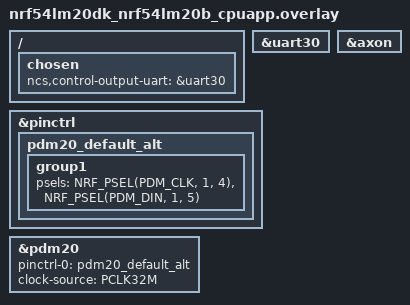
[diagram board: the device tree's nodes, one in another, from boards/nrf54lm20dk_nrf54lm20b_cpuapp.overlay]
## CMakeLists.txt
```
# SPDX-License-Identifier: Apache-2.0

cmake_minimum_required(VERSION 3.20.0)

# Include application-specific Kconfig before finding Zephyr
set(KCONFIG_ROOT ${CMAKE_CURRENT_SOURCE_DIR}/Kconfig)

find_package(Zephyr REQUIRED HINTS $ENV{ZEPHYR_BASE})
project(nrf54lm20b_wakeword_gated_kws)

# Note: The nrf_edgeai library is linked directly in zephyr/CMakeLists.txt using zephyr_link_libraries(),
# and the axon-ml SDK sources are added directly to Zephyr via zephyr_sources() in the same CMakeLists.txt.

target_sources(app PRIVATE src/main.cpp
    src/models/wakeword/nrf_edgeai_generated/nrf_edgeai_user_model.c
    src/models/kws/nrf_edgeai_generated/nrf_edgeai_user_model.c
    src/dmic.c
)
```

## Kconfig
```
# Application Kconfig
# This sources the Axon ML Kconfig options
source "Kconfig.zephyr"

rsource "../../lib/axon/zephyr/Kconfig.nrf_axon"
```

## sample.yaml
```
sample:
  description: Continuous DMIC audio pipeline that waits for the "Okay Nordic" wakeword, then runs nRF Edge AI keyword spotting in a 7-second active window and returns to wakeword mode on timeout.
  name: Wakeword gated KeyWord Spotting (KWS) application

common:
  sysbuild: true
  build_only: true
  tags:
    - axon
    - axon_audio_models
    - axon_wakeword_kws

tests:
  applications.wakeword_kws.zdebug:
    platform_allow:
      - nrf54lm20dk/nrf54lm20b/cpuapp
    integration_platforms:
      - nrf54lm20dk/nrf54lm20b/cpuapp
```

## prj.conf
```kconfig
# General project configuration for the snoring detection application
CONFIG_CPP=y
CONFIG_STD_CPP17=y
CONFIG_REQUIRES_FULL_LIBCPP=y
CONFIG_NEWLIB_LIBC=y
CONFIG_NEWLIB_LIBC_FLOAT_PRINTF=y
CONFIG_NEWLIB_LIBC_NANO=n
CONFIG_FPU=y

# Set the main thread stack size to accommodate the needs of the application
CONFIG_MAIN_STACK_SIZE=8192

# Enable PDM microphone support
CONFIG_AUDIO=y
CONFIG_AUDIO_DMIC=y

# Enable GPIO support
CONFIG_GPIO=y

# Enable logging for debugging purposes
CONFIG_LOG=y
CONFIG_LOG_MODE_IMMEDIATE=y
CONFIG_PRINTK=y
CONFIG_PRINTK_SYNC=y

# Enable verbose assertions for better debugging information
CONFIG_ASSERT_VERBOSE=y

# Enable the Nordic Semiconductor AXON neural network accelerator
CONFIG_NRF_AXON=y

# Axon model specific settings, if you have multiple models, these settings should be sufficient for the largest model
CONFIG_NRF_AXON_INTERLAYER_BUFFER_SIZE=6656
CONFIG_NRF_AXON_PSUM_BUFFER_SIZE=0
```

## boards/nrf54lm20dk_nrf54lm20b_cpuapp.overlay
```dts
/*
 * Copyright (c) 2026 Nordic Semiconductor ASA
 *
 * SPDX-License-Identifier: LicenseRef-Nordic-5-Clause
 */

/ {
    chosen {
        ncs,control-output-uart = &uart30;
    };
};

&uart30 {
    status = "okay";
};

&pinctrl {
    pdm20_default_alt: pdm20_default_alt {
        group1 {
            psels = <NRF_PSEL(PDM_CLK, 1, 4)>,
                    <NRF_PSEL(PDM_DIN, 1, 5)>;
        };
    };
};

dmic_dev: &pdm20 {
    status = "okay";
    pinctrl-0 = <&pdm20_default_alt>;
    pinctrl-names = "default";
    clock-source = "PCLK32M";
};

&axon {
    status = "okay";
};
```

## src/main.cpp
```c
#include <zephyr/kernel.h>

#include <string.h>

#include <nrf_edgeai/rt/nrf_edgeai_runtime.h>
#include <nrf_edgeai/rt/nrf_edgeai_runtime_aux.h>  // for utility functions nrf_edgeai_model_axon_init_persistent_vars

#include "models/wakeword/nrf_edgeai_generated/nrf_edgeai_user_model.h"
#include "models/kws/nrf_edgeai_generated/nrf_edgeai_user_model.h"

#include "dmic.h"

//////////////////////////////////////////////////////////////////////////////

#define MODEL_WAKEWORD_LABEL        "Okay Nordic"
#define KEYWORD_SPOTTING_TIMEOUT_MS 7000
#define DEMO_FINAL_DETECTIONS_ONLY  0
#define PRINT_RAW_PROBABILITY       1
#define PRINT_KEYWORD_CLASS_ACTIVITY 1

//////////////////////////////////////////////////////////////////////////////

typedef enum application_state_e
{
    APP_WAITING_FOR_WAKEWORD,
    APP_WAITING_FOR_KEYWORDS,
} application_state_t;

typedef enum keyword_labels_e
{
    KEYWORD_OFF     = 0,
    KEYWORD_ON    = 1,
    KEYWORD_OTHER     = 2,
    KEYWORD_SILENCE    = 3,
    KEYWORD_SWITCH     = 4,

    KEYWORDS_cnt
} keyword_labels_t;

typedef struct
{
    const char* name;
    size_t      count_needed;
    uint8_t     threshold_percent;
} keyword_class_cfg_t;

typedef struct
{
    bool     has_active_class;
    uint16_t predicted_class;
    size_t   count;
    size_t   non_keyword_count;
    uint16_t non_keyword_class;
    flt32_t  average_probability;
    bool     wait_for_class_change;
    uint16_t blocked_class;
} keyword_runtime_ctx_t;

typedef struct
{
    bool     has_first_keyword;
    uint16_t first_class;
    flt32_t  first_probability;
    uint32_t detected_at_ms;
} keyword_phrase_ctx_t;

//////////////////////////////////////////////////////////////////////////////

static bool is_wakeword_detected(flt32_t probability);
static void reset_keyword_detection_state(void);
static bool is_keyword_command_component(uint16_t predicted_class);
static bool is_keyword_phrase_first_word(uint16_t predicted_class);
static bool is_keyword_phrase_second_word(uint16_t predicted_class);
static bool is_valid_keyword_command_pair(uint16_t first_class, uint16_t second_class);
static const keyword_class_cfg_t* get_keyword_class_cfg(uint16_t predicted_class);
static bool is_keyword_probability_above_threshold(uint16_t predicted_class, flt32_t probability);
static bool try_detect_keyword_command(uint16_t     predicted_class,
                                       flt32_t      probability,
                                       const char** pp_first_keyword_name,
                                       const char** pp_second_keyword_name,
                                       bool*        p_has_second_keyword,
                                       uint8_t*     p_average_probability);

//////////////////////////////////////////////////////////////////////////////

static const keyword_class_cfg_t KEYWORD_CLASSES_CFG[] = {
    [KEYWORD_OFF] = { .name = "OFF", .count_needed = 2, .threshold_percent = 0 },
    [KEYWORD_ON] = { .name = "ON", .count_needed = 2, .threshold_percent = 0 },
    [KEYWORD_OTHER] = { .name = "OTHER", .count_needed = 4, .threshold_percent = 0 },
    [KEYWORD_SILENCE] = { .name = "SILENCE", .count_needed = 4, .threshold_percent = 0 },
    [KEYWORD_SWITCH] = { .name = "SWITCH", .count_needed = 2, .threshold_percent = 0 },
};

static keyword_runtime_ctx_t s_keyword_runtime_ctx;
static keyword_phrase_ctx_t  s_keyword_phrase_ctx;

//////////////////////////////////////////////////////////////////////////////

int main()
{
#if !DEMO_FINAL_DETECTIONS_ONLY
    printk("Starting Wakeword gated KWS Application...\n");
    printk("\tWakeword: %s\n", MODEL_WAKEWORD_LABEL);
    printk("\tSupported commands: MUSIC DOWN, MUSIC UP, NEXT TRACK, ");
    printk("PREVIOUS TRACK, PLAY MUSIC, STOP MUSIC\n");
    printk("\tIgnored classes: %s, %s\n",
           KEYWORD_CLASSES_CFG[KEYWORD_OTHER].name,
           KEYWORD_CLASSES_CFG[KEYWORD_SILENCE].name);

    nrf_edgeai_rt_version_t libver = nrf_edgeai_runtime_version();
    printk("Nordic Edge AI Library version: %d.%d.%d\n",
           libver.field.major,
           libver.field.minor,
           libver.field.patch);
#endif

    nrf_edgeai_t* p_wakeword_model = nrf_edgeai_user_model_92597();
    nrf_edgeai_t* p_kws_model      = nrf_edgeai_user_model_kws();

    // Initialize wakeword model
    nrf_edgeai_err_t res = nrf_edgeai_init(p_wakeword_model);
    __ASSERT(res == NRF_EDGEAI_ERR_SUCCESS,
             "Failed to initialize Wakeword Edge AI model, error code: %d\n",
             res);

    // Initialize keyword spotting model
    res = nrf_edgeai_init(p_kws_model);
    __ASSERT(res == NRF_EDGEAI_ERR_SUCCESS,
             "Failed to initialize KWS Edge AI model, error code: %d\n",
             res);

    // Initialize PDM microphone
    int err = dmic_init();
    __ASSERT(err == 0, "Failed to initialize DMIC, error code: %d\n", err);

    err = dmic_start();
    __ASSERT(err == 0, "Failed to start DMIC, error code: %d\n", err);

    void*  audio_buffer;
    size_t audio_buffer_size;

    const int32_t read_timeout   = 100;
    uint32_t      kws_start_time = 0;

    application_state_t app_state = APP_WAITING_FOR_WAKEWORD;
#if !DEMO_FINAL_DETECTIONS_ONLY
    printk("Waiting for wakeword...\n");
#endif

    while (true)
    {
        // Read audio data from DMIC,
        err = dmic_read_buffer(&audio_buffer, &audio_buffer_size, read_timeout);
        if (err < 0)
        {
            printk("Failed to read from DMIC (err %d)\n", err);
            continue;
        }

        size_t samples_num = audio_buffer_size / DMIC_SAMPLE_BYTES;

        switch (app_state)
        {
            case APP_WAITING_FOR_WAKEWORD:
            {
                res = nrf_edgeai_feed_inputs(p_wakeword_model, audio_buffer, samples_num);

                if (res != NRF_EDGEAI_ERR_SUCCESS) { break; }

                res = nrf_edgeai_run_inference(p_wakeword_model);

                if (res != NRF_EDGEAI_ERR_SUCCESS) { break; }

                uint16_t predicted_class = p_wakeword_model->decoded_output.classif.predicted_class;
                flt32_t  probability =
                    p_wakeword_model->decoded_output.classif.probabilities.p_f32[predicted_class];

                if (is_wakeword_detected(probability))
                {
#if !DEMO_FINAL_DETECTIONS_ONLY
                    printk("Wakeword detected! Starting keyword spotting...\n");
#endif
                    // Re-initialize KWS model to reset its state after wakeword detection
                    nrf_edgeai_model_axon_init_persistent_vars(p_kws_model);
                    reset_keyword_detection_state();
                    kws_start_time = k_uptime_get_32();
                    app_state      = APP_WAITING_FOR_KEYWORDS;
                }
            }
            break;
            case APP_WAITING_FOR_KEYWORDS:
            {
                if (k_uptime_get_32() - kws_start_time > KEYWORD_SPOTTING_TIMEOUT_MS)
                {
#if !DEMO_FINAL_DETECTIONS_ONLY
                    printk("Keyword spotting timeout\nWaiting for wakeword...\n");
#endif
                    // Re-initialize WW model to reset its state after keyword detection
                    nrf_edgeai_model_axon_init_persistent_vars(p_wakeword_model);
                    reset_keyword_detection_state();
                    app_state = APP_WAITING_FOR_WAKEWORD;
                    break;
                }

                res = nrf_edgeai_feed_inputs(p_kws_model, audio_buffer, samples_num);

                if (res != NRF_EDGEAI_ERR_SUCCESS) { break; }

                res = nrf_edgeai_run_inference(p_kws_model);

                if (res != NRF_EDGEAI_ERR_SUCCESS) { break; }

                uint16_t predicted_class = p_kws_model->decoded_output.classif.predicted_class;
                flt32_t  probability =
                    p_kws_model->decoded_output.classif.probabilities.p_f32[predicted_class];

                const char* first_keyword_name      = NULL;
                const char* second_keyword_name     = NULL;
                bool        has_second_keyword      = false;
                uint8_t     average_probability_pct = 0;

                if (try_detect_keyword_command(predicted_class,
                                               probability,
                                               &first_keyword_name,
                                               &second_keyword_name,
                                               &has_second_keyword,
                                               &average_probability_pct))
                {

                    printk("Keyword detected: %s, %d %%\n",
                            first_keyword_name,
                            average_probability_pct);

                    /* Return to wakeword mode immediately after a valid command. */
                    nrf_edgeai_model_axon_init_persistent_vars(p_wakeword_model);
                    reset_keyword_detection_state();
                    app_state = APP_WAITING_FOR_WAKEWORD;

#if !DEMO_FINAL_DETECTIONS_ONLY
                    printk("Waiting for wakeword...\n");
#endif
                }
            }
            break;

            default:
                break;
        }

        dmic_free_buffer(audio_buffer);
    }

    return 0;
}

//////////////////////////////////////////////////////////////////////////////

static void reset_keyword_detection_state(void)
{
    memset(&s_keyword_runtime_ctx, 0, sizeof(s_keyword_runtime_ctx));
    memset(&s_keyword_phrase_ctx, 0, sizeof(s_keyword_phrase_ctx));
}

//////////////////////////////////////////////////////////////////////////////

static bool is_keyword_command_component(uint16_t predicted_class)
{
    return (predicted_class < KEYWORDS_cnt) && (predicted_class != KEYWORD_OTHER) &&
           (predicted_class != KEYWORD_SILENCE);
}

//////////////////////////////////////////////////////////////////////////////

static bool is_keyword_phrase_first_word(uint16_t predicted_class)
{
    return (predicted_class == KEYWORD_ON) || (predicted_class == KEYWORD_OFF) ||
           (predicted_class == KEYWORD_SWITCH);
}

//////////////////////////////////////////////////////////////////////////////


static const keyword_class_cfg_t* get_keyword_class_cfg(uint16_t predicted_class)
{
    __ASSERT(predicted_class < KEYWORDS_cnt, "Invalid keyword class: %u", predicted_class);
    return &KEYWORD_CLASSES_CFG[predicted_class];
}

//////////////////////////////////////////////////////////////////////////////

static bool is_keyword_probability_above_threshold(uint16_t predicted_class, flt32_t probability)
{
    const keyword_class_cfg_t* p_class_cfg = get_keyword_class_cfg(predicted_class);

    if (p_class_cfg->threshold_percent == 0)
    {
        return true;
    }

    return (probability * 100.0f) >= (flt32_t)p_class_cfg->threshold_percent;
}

//////////////////////////////////////////////////////////////////////////////

static bool is_wakeword_detected(flt32_t probability)
{
#define THRESHOLD  0.85f
#define POS_IN_ROW 14
    static bool   result_row[POS_IN_ROW];
    static size_t filled = 0;

    /* move result by 1 position*/
    for (int i = 0; i < POS_IN_ROW - 1; i++)
    {
        result_row[i] = result_row[i + 1];
    }

    result_row[POS_IN_ROW - 1] = (probability > THRESHOLD);

    if (filled < POS_IN_ROW)
    {
        filled++;
    }

    if (filled < POS_IN_ROW)
    {
        return false;
    }

    for (int i = 0; i < POS_IN_ROW; i++)
    {
        if (!result_row[i])
        {
#if PRINT_RAW_PROBABILITY
            printk("Wakeword window fill: %u \tprob : %0.3f\n", (unsigned int)filled, probability);
#endif
            return false;
        }
    }

#if PRINT_RAW_PROBABILITY
    printk("Wakeword window fill: %u \tprob : %0.3f\n", (unsigned int)filled, probability);
#endif

    return true;
}

//////////////////////////////////////////////////////////////////////////////

static bool try_detect_keyword_command(uint16_t     predicted_class,
                                       flt32_t      probability,
                                       const char** pp_first_keyword_name,
                                       const char** pp_second_keyword_name,
                                       bool*        p_has_second_keyword,
                                       uint8_t*     p_average_probability)
{
    const keyword_class_cfg_t* p_class_cfg          = get_keyword_class_cfg(predicted_class);
    const bool                 is_command_component =
        is_keyword_command_component(predicted_class);
    const bool passes_threshold =
        is_command_component && is_keyword_probability_above_threshold(predicted_class, probability);

    *pp_first_keyword_name = NULL;
    *pp_second_keyword_name = NULL;
    *p_has_second_keyword = false;
    *p_average_probability = 0;

    const uint32_t now_ms = k_uptime_get_32();

    if (s_keyword_runtime_ctx.wait_for_class_change)
    {
        if (predicted_class == s_keyword_runtime_ctx.blocked_class)
        {
            return false;
        }

        s_keyword_runtime_ctx.wait_for_class_change = false;
    }

    if (!passes_threshold)
    {
        if (is_command_component)
        {
            /* A low-confidence keyword should break the current confirmation streak. */
            s_keyword_runtime_ctx.has_active_class    = false;
            s_keyword_runtime_ctx.count               = 0;
            s_keyword_runtime_ctx.average_probability = 0;
        }

        if ((s_keyword_runtime_ctx.non_keyword_count == 0) ||
            (s_keyword_runtime_ctx.non_keyword_class != predicted_class))
        {
            s_keyword_runtime_ctx.non_keyword_class = predicted_class;
            s_keyword_runtime_ctx.non_keyword_count = 0;
        }

        s_keyword_runtime_ctx.non_keyword_count++;

        if (s_keyword_phrase_ctx.has_first_keyword &&
            (s_keyword_runtime_ctx.non_keyword_count < p_class_cfg->count_needed))
        {
            /* Keep the first word alive across short OTHER/SILENCE gaps. */
            s_keyword_phrase_ctx.detected_at_ms = now_ms;
        }

        if (s_keyword_runtime_ctx.non_keyword_count >= p_class_cfg->count_needed)
        {
            s_keyword_runtime_ctx.has_active_class    = false;
            s_keyword_runtime_ctx.count               = 0;
            s_keyword_runtime_ctx.non_keyword_count   = 0;
            s_keyword_runtime_ctx.non_keyword_class   = 0;
            s_keyword_runtime_ctx.average_probability = 0;
        }

        return false;
    }

    s_keyword_runtime_ctx.non_keyword_count = 0;

    if (!s_keyword_runtime_ctx.has_active_class ||
        (predicted_class != s_keyword_runtime_ctx.predicted_class))
    {
        s_keyword_runtime_ctx.has_active_class    = true;
        s_keyword_runtime_ctx.predicted_class     = predicted_class;
        s_keyword_runtime_ctx.count               = 0;
        s_keyword_runtime_ctx.non_keyword_count   = 0;
        s_keyword_runtime_ctx.non_keyword_class   = 0;
        s_keyword_runtime_ctx.average_probability = 0;
    }

    s_keyword_runtime_ctx.count++;
    s_keyword_runtime_ctx.average_probability +=
        (probability - s_keyword_runtime_ctx.average_probability) / s_keyword_runtime_ctx.count;

    if (s_keyword_phrase_ctx.has_first_keyword)
    {
        /* Any ongoing keyword activity extends the pairing window. */
        s_keyword_phrase_ctx.detected_at_ms = now_ms;
    }

#if !DEMO_FINAL_DETECTIONS_ONLY && PRINT_KEYWORD_CLASS_ACTIVITY
    printk("Keyword model class %s, count: %u \tprob : %0.3f\n",
           get_keyword_class_cfg(s_keyword_runtime_ctx.predicted_class)->name,
           (unsigned int)s_keyword_runtime_ctx.count,
           s_keyword_runtime_ctx.average_probability);
#endif

    if (s_keyword_runtime_ctx.count < p_class_cfg->count_needed)
    {
        return false;
    }

    const flt32_t detected_probability = s_keyword_runtime_ctx.average_probability;

    s_keyword_runtime_ctx.has_active_class      = false;
    s_keyword_runtime_ctx.count                 = 0;
    s_keyword_runtime_ctx.non_keyword_count     = 0;
    s_keyword_runtime_ctx.non_keyword_class     = 0;
    s_keyword_runtime_ctx.average_probability   = 0;
    s_keyword_runtime_ctx.wait_for_class_change = true;
    s_keyword_runtime_ctx.blocked_class         = predicted_class;


    if (is_keyword_phrase_first_word(predicted_class))
    {
        s_keyword_phrase_ctx.first_class       = predicted_class;
        s_keyword_phrase_ctx.first_probability = detected_probability;
        s_keyword_phrase_ctx.detected_at_ms    = now_ms;
#if !DEMO_FINAL_DETECTIONS_ONLY
        printk("First keyword detected: %s\n", p_class_cfg->name);
#endif
        return false;
    }

    /* Unsupported combinations are ignored, but the confirmed first word stays active. */
    return false;
}





// 0	OFF
// 1	ON
// 2	OTHER
// 3	SILENCE
// 4	SWITCH
```

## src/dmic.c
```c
/*
 * Copyright (c) 2026 Nordic Semiconductor ASA
 *
 * SPDX-License-Identifier: LicenseRef-Nordic-5-Clause
 */

#include <stddef.h>

#include <zephyr/audio/dmic.h>
#include <zephyr/device.h>
#include <zephyr/devicetree.h>
#include <zephyr/kernel.h>

#include "dmic.h"

//////////////////////////////////////////////////////////////////////////////

#define BLOCK_SIZE (DMIC_SAMPLE_BYTES * DMIC_PCM_RATE * SAMPLES_BLOCK_LENGTH_MS / 1000)
#define DMIC_BUFFER_BLOCKS 16

/* Extra buffering helps tolerate slow synchronous debug prints. */
K_MEM_SLAB_DEFINE_STATIC(dmic_mem_slab, BLOCK_SIZE, DMIC_BUFFER_BLOCKS, 4);
static const struct device* const dmic_dev = DEVICE_DT_GET(DT_NODELABEL(dmic_dev));

//////////////////////////////////////////////////////////////////////////////

int dmic_init(void)
{
    int err;

    if (!device_is_ready(dmic_dev))
    {
        printk("Device is not ready\n");
        return -ENODEV;
    }

    struct pcm_stream_cfg stream = {
        .pcm_rate   = DMIC_PCM_RATE,
        .pcm_width  = DMIC_SAMPLE_BYTES * 8,
        .block_size = BLOCK_SIZE,
        .mem_slab   = &dmic_mem_slab,
    };
    struct dmic_cfg cfg = {
		.io = {
			.min_pdm_clk_freq = 1000000,
			.max_pdm_clk_freq = 3250000,
			.min_pdm_clk_dc = 40,
			.max_pdm_clk_dc = 60,
		},
		.streams = &stream,
		.channel = {
			.req_chan_map_lo = dmic_build_channel_map(0, 0, PDM_CHAN_LEFT),
			.req_chan_map_hi = 0,
			.req_num_chan = 1,
			.req_num_streams = 1,
		},
	};

    err = dmic_configure(dmic_dev, &cfg);
    if (err < 0)
    {
        printk("Failed to configure (err %d)\n", err);
        return err;
    }

    return 0;
}

//////////////////////////////////////////////////////////////////////////////

int dmic_start(void)
{
    return dmic_trigger(dmic_dev, DMIC_TRIGGER_START);
}

//////////////////////////////////////////////////////////////////////////////

int dmic_read_buffer(void** audio_buffer, size_t* audio_buffer_size, int32_t timeout_ms)
{
    return dmic_read(dmic_dev, 0, audio_buffer, audio_buffer_size, timeout_ms);
}

//////////////////////////////////////////////////////////////////////////////
void dmic_free_buffer(void* buffer)
{
    k_mem_slab_free(&dmic_mem_slab, buffer);
}
```

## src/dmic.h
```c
/*
 * Copyright (c) 2026 Nordic Semiconductor ASA
 *
 * SPDX-License-Identifier: LicenseRef-Nordic-5-Clause
 */

/**
 * @defgroup dmic DMIC control functions
 * @{
 */

#ifndef __DMIC_H__
#define __DMIC_H__

#ifdef __cplusplus
extern "C" {
#endif /* __cplusplus */

#define DMIC_SAMPLE_BYTES       (2)
#define DMIC_PCM_RATE           (16000)
#define SAMPLES_BLOCK_LENGTH_MS (10)

/**
 * @brief Initialize DMIC.
 *
 * @return Operation status result, 0 for success.
 */
int dmic_init(void);

/**
 * @brief Trigger DMIC start.
 *
 * @return Operation status result, 0 for success.
 */
int dmic_start(void);

/**
 * @brief Read one audio block from DMIC.
 *
 * @param[out] audio_buffer      Pointer to returned audio buffer.
 * @param[out] audio_buffer_size Size of returned audio buffer in bytes.
 * @param[in]  timeout_ms        Read timeout in milliseconds.
 *
 * @return Operation status result, 0 for success.
 */
int dmic_read_buffer(void** audio_buffer, size_t* audio_buffer_size, int32_t timeout_ms);

/**
 * @brief Free the audio buffer acquired with @c dmic_read.
 *
 * @param buffer Audio buffer.
 */
void dmic_free_buffer(void* buffer);

#ifdef __cplusplus
}
#endif /* __cplusplus */

#endif /* __DMIC_H__ */

/**
 * @}
 */
```
